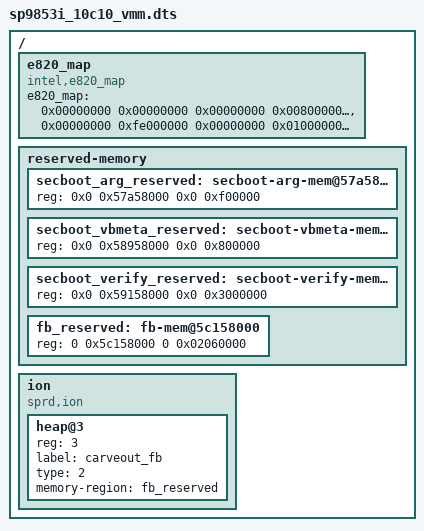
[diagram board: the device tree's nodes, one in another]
/*
 * Spreadtrum sc9853i_10c10 vmm board DTS file
 *
 * Copyright (C) 2015, Spreadtrum Communications Inc.
 *
 * This file is licensed under a dual GPLv2 or X11 license.
 */

/dts-v1/;

#include "sc9853i_vmm.dtsi"
#include <dt-bindings/e820/e820.h>

/ {

	e820_map {
		#address-cells = <2>;
		#size-cells = <2>;
		compatible = "intel,e820_map";

		/* element array: addr(64), size(64), type*/
		e820_map =  <0x00000000 0x00000000 0x00000000 0x00800000 E820_RESERVED>, /* vmm reserve */
			<0x00000000 0xfe000000 0x00000000 0x01000000 E820_RESERVED>; /* reserve */
	};
	reserved-memory {
		#address-cells = <2>;
                #size-cells = <2>;
                ranges;

		secboot_arg_reserved: secboot-arg-mem@57a58000{
			reg = <0x0 0x57a58000 0x0 0xf00000>;
		};

		secboot_vbmeta_reserved: secboot-vbmeta-mem@58958000{
			reg = <0x0 0x58958000 0x0 0x800000>;
		};

		secboot_verify_reserved: secboot-verify-mem@59158000{
			reg = <0x0 0x59158000 0x0 0x3000000>;
		};

		/* fb */
		fb_reserved: fb-mem@5c158000{
			reg = <0 0x5c158000 0 0x02060000>;
		};
	};

	ion {
		compatible = "sprd,ion";
		#address-cells = <1>;
                #size-cells = <0>;
		heap@3 {
			reg = <3>;
			label = "carveout_fb";
			type = <2>;
			memory-region = <&fb_reserved>;
		};
	};
};
